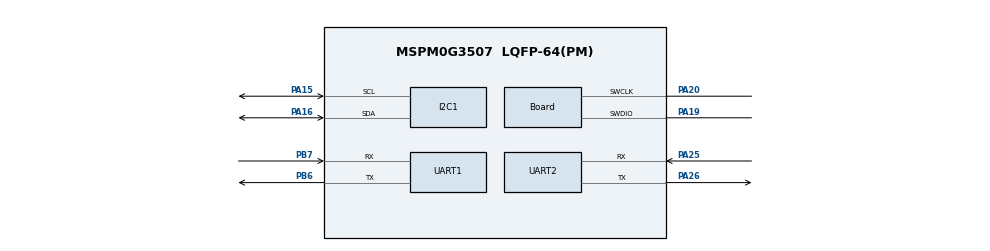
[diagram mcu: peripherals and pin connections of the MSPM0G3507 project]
/**
 * These arguments were used when this file was generated. They will be automatically applied on subsequent loads
 * via the GUI or CLI. Run CLI with '--help' for additional information on how to override these arguments.
 * @cliArgs --device "MSPM0G350X" --part "Default" --package "LQFP-64(PM)" --product "mspm0_sdk@2.11.00.07"
 * @v2CliArgs --device "MSPM0G3507" --package "LQFP-64(PM)" --product "mspm0_sdk@2.11.00.07"
 * @versions {"tool":"1.26.2+4477"}
 */

/**
 * Import the modules used in this configuration.
 */
const I2C           = scripting.addModule("/ti/driverlib/I2C", {}, false);
const I2C1          = I2C.addInstance();
const SYSCTL        = scripting.addModule("/ti/driverlib/SYSCTL");
const UART          = scripting.addModule("/ti/driverlib/UART", {}, false);
const UART1         = UART.addInstance();
const UART2         = UART.addInstance();
const UART3         = UART.addInstance();
const ProjectConfig = scripting.addModule("/ti/project_config/ProjectConfig");

/**
 * Write custom configuration values to the imported modules.
 */
I2C1.$name                     = "I2C_0";
I2C1.basicEnableController     = true;
I2C1.peripheral.sdaPin.$assign = "PA16";
I2C1.peripheral.sclPin.$assign = "PA15";
I2C1.sdaPinConfig.$name        = "ti_driverlib_gpio_GPIOPinGeneric0";
I2C1.sclPinConfig.$name        = "ti_driverlib_gpio_GPIOPinGeneric1";

const Board                       = scripting.addModule("/ti/driverlib/Board", {}, false);
Board.peripheral.$assign          = "DEBUGSS";
Board.peripheral.swclkPin.$assign = "PA20";
Board.peripheral.swdioPin.$assign = "PA19";

SYSCTL.clockTreeEn = true;

UART1.targetBaudRate                   = 115200;
UART1.enableFIFO                       = true;
UART1.rxFifoThreshold                  = "DL_UART_RX_FIFO_LEVEL_ONE_ENTRY";
UART1.enableDMARX                      = false;
UART1.enableDMATX                      = false;
UART1.$name                            = "UART_1";
UART1.peripheral.$assign               = "UART1";
UART1.peripheral.rxPin.$assign         = "PB7";
UART1.peripheral.txPin.$assign         = "PB6";
UART1.txPinConfig.$name                = "ti_driverlib_gpio_GPIOPinGeneric2";
UART1.txPinConfig.direction            = scripting.forceWrite("OUTPUT");
UART1.txPinConfig.hideOutputInversion  = scripting.forceWrite(false);
UART1.txPinConfig.onlyInternalResistor = scripting.forceWrite(false);
UART1.txPinConfig.passedPeripheralType = scripting.forceWrite("Digital");
UART1.rxPinConfig.$name                = "ti_driverlib_gpio_GPIOPinGeneric3";
UART1.rxPinConfig.hideOutputInversion  = scripting.forceWrite(false);
UART1.rxPinConfig.onlyInternalResistor = scripting.forceWrite(false);
UART1.rxPinConfig.passedPeripheralType = scripting.forceWrite("Digital");

UART2.targetBaudRate                   = 115200;
UART2.$name                            = "UART_IMU";
UART2.enableFIFO                       = true;
UART2.enabledInterrupts                = ["RX"];
UART2.rxFifoThreshold                  = "DL_UART_RX_FIFO_LEVEL_ONE_ENTRY";
UART2.peripheral.$assign               = "UART3";
UART2.peripheral.rxPin.$assign         = "PA25";
UART2.peripheral.txPin.$assign         = "PA26";
UART2.txPinConfig.$name                = "ti_driverlib_gpio_GPIOPinGeneric4";
UART2.txPinConfig.direction            = scripting.forceWrite("OUTPUT");
UART2.txPinConfig.hideOutputInversion  = scripting.forceWrite(false);
UART2.txPinConfig.onlyInternalResistor = scripting.forceWrite(false);
UART2.txPinConfig.passedPeripheralType = scripting.forceWrite("Digital");
UART2.rxPinConfig.$name                = "ti_driverlib_gpio_GPIOPinGeneric5";
UART2.rxPinConfig.hideOutputInversion  = scripting.forceWrite(false);
UART2.rxPinConfig.onlyInternalResistor = scripting.forceWrite(false);
UART2.rxPinConfig.passedPeripheralType = scripting.forceWrite("Digital");

UART3.$name                            = "UART_K230";
UART3.targetBaudRate                   = 115200;
UART3.enabledInterrupts                = ["RX"];
UART3.peripheral.$assign               = "UART2";
UART3.txPinConfig.$name                = "ti_driverlib_gpio_GPIOPinGeneric6";
UART3.txPinConfig.direction            = scripting.forceWrite("OUTPUT");
UART3.txPinConfig.hideOutputInversion  = scripting.forceWrite(false);
UART3.txPinConfig.onlyInternalResistor = scripting.forceWrite(false);
UART3.txPinConfig.passedPeripheralType = scripting.forceWrite("Digital");
UART3.rxPinConfig.$name                = "ti_driverlib_gpio_GPIOPinGeneric7";
UART3.rxPinConfig.hideOutputInversion  = scripting.forceWrite(false);
UART3.rxPinConfig.onlyInternalResistor = scripting.forceWrite(false);
UART3.rxPinConfig.passedPeripheralType = scripting.forceWrite("Digital");

ProjectConfig.deviceSpin = "MSPM0G3507";

/**
 * Pinmux solution for unlocked pins/peripherals. This ensures that minor changes to the automatic solver in a future
 * version of the tool will not impact the pinmux you originally saw.  These lines can be completely deleted in order to
 * re-solve from scratch.
 */
I2C1.peripheral.$suggestSolution        = "I2C1";
UART3.peripheral.rxPin.$suggestSolution = "PA22";
UART3.peripheral.txPin.$suggestSolution = "PA21";
